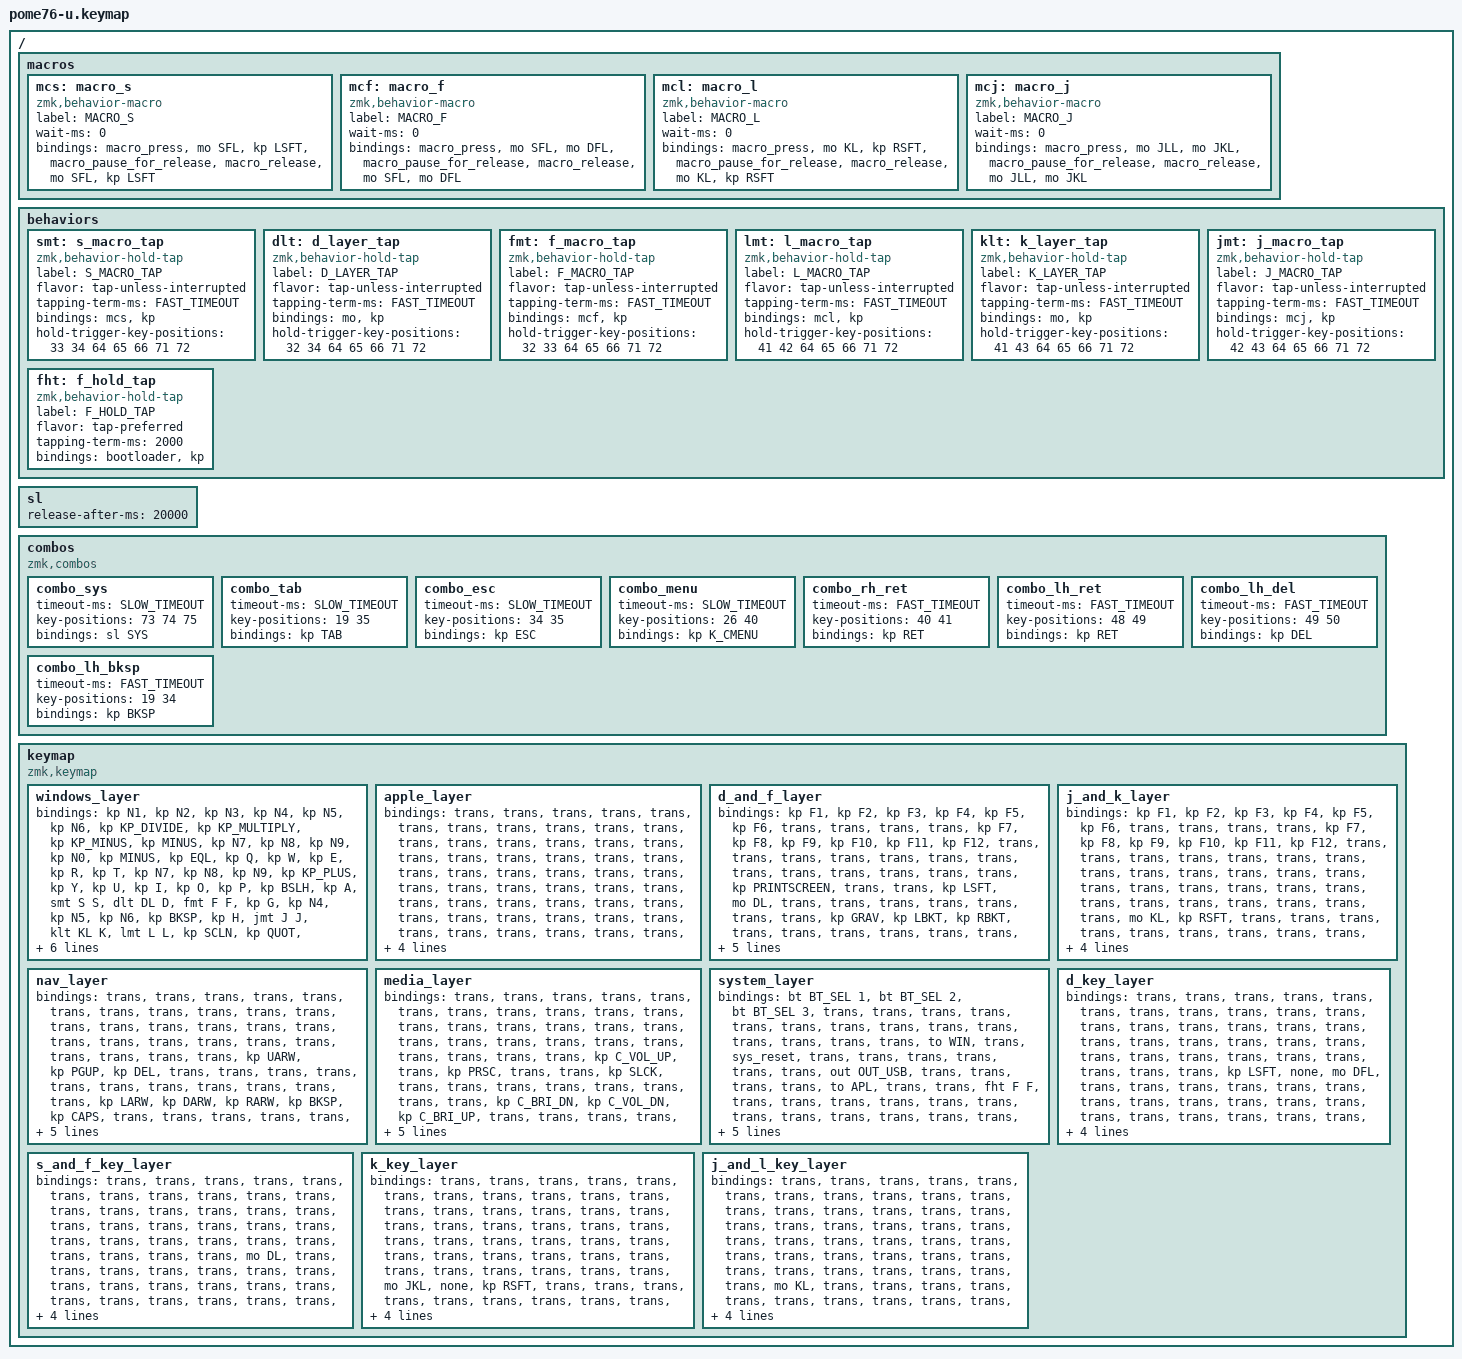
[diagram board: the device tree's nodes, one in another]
#include <behaviors.dtsi>
#include <dt-bindings/zmk/bt.h>
#include <dt-bindings/zmk/keys.h>
#include <dt-bindings/zmk/outputs.h>

// ***********************************************************************************
// Key positions
// ***********************************************************************************
// 19: R
// 26: U
// 32: S
// 41: J
// 46: Left Shift (start of Z row)
// 57: M
// 61: start of bottom row
// (64, 65, 66): left hand modifier keys
// 70: Space

// ***********************************************************************************
// Layer enums
// ***********************************************************************************
#define WIN 0     // Windows
#define APL 1     // Apple
#define DFL 2     // Layer that is controlled by the D or F keys
#define JKL 3     // Layer that is controlled by the J or K keys
#define NAV 4     // Navigation
#define MED 5     // Media
#define SYS 6     // System
#define DL  7     // Layer that is controlled by the D key
#define SFL 8     // Layer that is controlled by the S or F keys
#define KL  9     // Layer that is controlled by the K key
#define JLL 10    // Layer that is controlled by the J or L keys

// ***********************************************************************************
// Timeouts
// ***********************************************************************************
// FAST_TIMEOUT is very short.
// It is used mostly for combos involving keys that might occur in sequence while typing common words.
// For example SD => Shift, because S and D occur next to each other common words like "sounDS".
// See mercury-u.keymap for the early history of FAST_TIMEOUT values.
// [12Nov2023] 50 => 35 ms Decrease timout due to (fairly rare) unintentional combo activations. E.g. the word "sounds" comes out as "sounSHIFT".
// [03Nov2024] 35 => 42 ms Increase timout. I physically modified my switches by adding shims to the center posts to reduce key travel. After
//   this modification, SD is sometimes coming out as "sd" instead of the intended LShift.
// [26Dec2024] 42 => 46 ms Increase timout. ,. => Enter sometimes comes out as ,. instead of the intended Enter
#define FAST_TIMEOUT 42

// SLOW_TIMEOUT is very long.
// It is mostly used for combos involving keys that are controlled by the same finger, and should therefore by typed relatively slowly and in strict sequence.
// For example RG => TAB, because R and G are both actuated by the left index finger.
// [?? 2022] Initialize 200 ms. Naively chosen to mimic QMK's default value of TAPPING_TERM.
// [14Feb2025] Lower to 70 ms. Long timeout interferes with gaming. For example, F+G = ESC doesn't work well with F = Nova in Diablo 2.
#define SLOW_TIMEOUT 70

/ {
    // ***********************************************************************************
    // Macros
    // ***********************************************************************************
    macros {

        // ***********************************************************************************
        // Combo based layers
        // ***********************************************************************************
        mcs: macro_s {
            label = "MACRO_S";
            compatible = "zmk,behavior-macro";
            #binding-cells = <0>;
            wait-ms = <0>;
            bindings
                = <&macro_press &mo SFL &kp LSFT>
                , <&macro_pause_for_release>
                , <&macro_release &mo SFL &kp LSFT>
                ;
        };

        mcf: macro_f {
            label = "MACRO_F";
            compatible = "zmk,behavior-macro";
            #binding-cells = <0>;
            wait-ms = <0>;
            bindings
                = <&macro_press &mo SFL &mo DFL>
                , <&macro_pause_for_release>
                , <&macro_release &mo SFL &mo DFL>
                ;
        };

        mcl: macro_l {
            label = "MACRO_L";
            compatible = "zmk,behavior-macro";
            #binding-cells = <0>;
            wait-ms = <0>;
            bindings
                = <&macro_press &mo KL &kp RSFT>
                , <&macro_pause_for_release>
                , <&macro_release &mo KL &kp RSFT>
                ;
        };

        mcj: macro_j {
            label = "MACRO_J";
            compatible = "zmk,behavior-macro";
            #binding-cells = <0>;
            wait-ms = <0>;
            bindings
                = <&macro_press &mo JLL &mo JKL>
                , <&macro_pause_for_release>
                , <&macro_release &mo JLL &mo JKL>
                ;
        };
    };

    // ***********************************************************************************
    // Hold-Taps
    // ***********************************************************************************
    behaviors {

        // ***********************************************************************************
        // Combo based layers
        // ***********************************************************************************
        smt: s_macro_tap {
            compatible = "zmk,behavior-hold-tap";
            label = "S_MACRO_TAP";
            #binding-cells = <2>;
            flavor = "tap-unless-interrupted";
            tapping-term-ms = <FAST_TIMEOUT>;
            bindings = <&mcs>, <&kp>;
            hold-trigger-key-positions = <33 34 64 65 66 71 72>;
        };

        dlt: d_layer_tap {
            compatible = "zmk,behavior-hold-tap";
            label = "D_LAYER_TAP";
            #binding-cells = <2>;
            flavor = "tap-unless-interrupted";
            tapping-term-ms = <FAST_TIMEOUT>;
            bindings = <&mo>, <&kp>;
            hold-trigger-key-positions = <32 34 64 65 66 71 72>;
        };

        fmt: f_macro_tap {
            compatible = "zmk,behavior-hold-tap";
            label = "F_MACRO_TAP";
            #binding-cells = <2>;
            flavor = "tap-unless-interrupted";
            tapping-term-ms = <FAST_TIMEOUT>;
            bindings = <&mcf>, <&kp>;
            hold-trigger-key-positions = <32 33 64 65 66 71 72>;
        };

        lmt: l_macro_tap {
            compatible = "zmk,behavior-hold-tap";
            label = "L_MACRO_TAP";
            #binding-cells = <2>;
            flavor = "tap-unless-interrupted";
            tapping-term-ms = <FAST_TIMEOUT>;
            bindings = <&mcl>, <&kp>;
            hold-trigger-key-positions = <41 42 64 65 66 71 72>;
        };

        klt: k_layer_tap {
            compatible = "zmk,behavior-hold-tap";
            label = "K_LAYER_TAP";
            #binding-cells = <2>;
            flavor = "tap-unless-interrupted";
            tapping-term-ms = <FAST_TIMEOUT>;
            bindings = <&mo>, <&kp>;
            hold-trigger-key-positions = <41 43 64 65 66 71 72>;
        };

        jmt: j_macro_tap {
            compatible = "zmk,behavior-hold-tap";
            label = "J_MACRO_TAP";
            #binding-cells = <2>;
            flavor = "tap-unless-interrupted";
            tapping-term-ms = <FAST_TIMEOUT>;
            bindings = <&mcj>, <&kp>;
            hold-trigger-key-positions = <42 43 64 65 66 71 72>;
        };

        // ***********************************************************************************
        // Other hold-taps
        // ***********************************************************************************

        // F-key (in system_layer): hold = flash, tap = F
        fht: f_hold_tap {
            compatible = "zmk,behavior-hold-tap";
            label = "F_HOLD_TAP";
            #binding-cells = <2>;
            flavor = "tap-preferred";
            tapping-term-ms = <2000>;
            bindings = <&bootloader>, <&kp>;
        };
    };

    // sl stands for Sticky Layer.
    sl {
        release-after-ms = <20000>; // 20 seconds
    };

    // ***********************************************************************************
    // Combos
    // ***********************************************************************************
    combos {
        compatible = "zmk,combos";

        combo_sys {
            timeout-ms = <SLOW_TIMEOUT>;
            key-positions = <73 74 75>; /* lower right hand corner */
            bindings = <&sl SYS>;
        };
        combo_tab {
            timeout-ms = <SLOW_TIMEOUT>;
            key-positions = <19 35>; /* R G */
            bindings = <&kp TAB>;
        };
        combo_esc {
            timeout-ms = <SLOW_TIMEOUT>;
            key-positions = <34 35>; /* F G */
            bindings = <&kp ESC>;
        };
        combo_menu {
            timeout-ms = <SLOW_TIMEOUT>;
            key-positions = <26 40>; /* U H */
            bindings = <&kp K_CMENU>;
        };

        // Combos to make one-handed operation easier
        combo_rh_ret {
            // Previous timeouts:
            timeout-ms = <FAST_TIMEOUT>;
            key-positions = <40 41>; /* h j */
            bindings = <&kp RET>;
        };

        combo_lh_ret {
            // Previous timeouts:
            timeout-ms = <FAST_TIMEOUT>;
            key-positions = <48 49>; /* X C */
            bindings = <&kp RET>;
        };
        combo_lh_del {
            // Previous timeouts:
            timeout-ms = <FAST_TIMEOUT>;
            key-positions = <49 50>; /* C V */
            bindings = <&kp DEL>;
        };
        combo_lh_bksp {
            // Previous timeouts:
            timeout-ms = <FAST_TIMEOUT>;
            key-positions = <19 34 >; /* R F */
            bindings = <&kp BKSP>;
        };
    };

    // ***********************************************************************************
    // Keymaps
    // ***********************************************************************************
    keymap {
        compatible = "zmk,keymap";

        windows_layer {
            bindings = <
&kp N1        &kp N2        &kp N3        &kp N4        &kp N5        &kp N6       &kp KP_DIVIDE &kp KP_MULTIPLY &kp KP_MINUS &kp MINUS     &kp N7        &kp N8        &kp N9        &kp N0        &kp MINUS     &kp EQL
&kp Q         &kp W         &kp E         &kp R         &kp T         &kp N7        &kp N8        &kp N9        &kp KP_PLUS   &kp Y         &kp U         &kp I         &kp O         &kp P         &kp BSLH
&kp A         &smt S S      &dlt DL D     &fmt F F      &kp G         &kp N4        &kp N5        &kp N6        &kp BKSP      &kp H         &jmt J J      &klt KL K     &lmt L L      &kp SCLN      &kp QUOT
&kp LSFT      &kp Z         &kp X         &kp C         &kp V         &kp B         &kp N1        &kp N2        &kp N3        &kp BSLH      &kp N         &kp M         &kp CMMA      &kp DOT       &kp FSLH
&kp BKSP      &kp DEL       &kp SPC       &kp LGUI      &kp LCTL      &kp LALT      &kp SPC       &kp N0        &kp DOT       &kp SPC       &mo NAV       &mo MED       &kp BKSP      &kp DEL       &kp RET
            >;
        };

        apple_layer {
            bindings = <
&trans        &trans        &trans        &trans        &trans        &trans        &trans        &trans        &trans        &trans        &trans        &trans        &trans        &trans        &trans        &trans
&trans        &trans        &trans        &trans        &trans        &trans        &trans        &trans        &trans        &trans        &trans        &trans        &trans        &trans        &trans
&trans        &trans        &trans        &trans        &trans        &trans        &trans        &trans        &trans        &trans        &trans        &trans        &trans        &trans        &trans
&trans        &trans        &trans        &trans        &trans        &trans        &trans        &trans        &trans        &trans        &trans        &trans        &trans        &trans        &trans
&trans        &trans        &trans        &kp LALT      &kp LGUI      &kp LCTL      &trans        &trans        &trans        &trans        &trans        &trans        &trans        &trans        &trans
            >;
        };

        d_and_f_layer {
            bindings = <
&kp F1        &kp F2        &kp F3        &kp F4        &kp F5        &kp F6        &trans        &trans        &trans        &trans        &kp F7        &kp F8        &kp F9        &kp F10       &kp F11       &kp F12
&trans        &trans        &trans        &trans        &trans        &trans        &trans        &trans        &trans        &trans        &trans        &trans        &trans     &kp PRINTSCREEN  &trans
&trans        &kp LSFT      &mo DL        &trans        &trans        &trans        &trans        &trans        &trans        &trans        &kp GRAV      &kp LBKT      &kp RBKT      &trans        &trans
&trans        &trans        &trans        &trans        &trans        &trans        &trans        &trans        &trans        &trans        &trans        &trans        &trans        &trans        &trans
&trans        &trans        &trans        &trans        &trans        &trans        &trans        &trans        &trans        &trans        &trans        &trans        &trans        &trans        &trans
            >;
        };

        j_and_k_layer {
            bindings = <
&kp F1        &kp F2        &kp F3        &kp F4        &kp F5        &kp F6        &trans        &trans        &trans        &trans        &kp F7        &kp F8        &kp F9        &kp F10       &kp F11       &kp F12
&trans        &trans        &trans        &trans        &trans        &trans        &trans        &trans        &trans        &trans        &trans        &trans        &trans        &trans        &trans
&trans        &trans        &trans        &trans        &trans        &trans        &trans        &trans        &trans        &trans        &trans        &mo KL        &kp RSFT      &trans        &trans
&trans        &trans        &trans        &trans        &trans        &trans        &trans        &trans        &trans        &trans        &trans        &trans        &trans        &trans        &trans
&trans        &trans        &trans        &trans        &trans        &trans        &trans        &trans        &trans        &trans        &trans        &trans        &trans        &trans        &trans
            >;
        };

        nav_layer {
            bindings = <
&trans        &trans        &trans        &trans        &trans        &trans        &trans        &trans        &trans        &trans        &trans        &trans        &trans        &trans        &trans        &trans
&trans        &trans        &trans        &trans        &trans        &trans        &trans        &trans        &trans        &trans        &trans        &kp UARW      &kp PGUP      &kp DEL       &trans
&trans        &trans        &trans        &trans        &trans        &trans        &trans        &trans        &trans        &trans        &kp LARW      &kp DARW      &kp RARW      &kp BKSP      &kp CAPS
&trans        &trans        &trans        &trans        &trans        &trans        &trans        &trans        &trans        &trans        &kp PGDN      &kp RGUI      &kp HOME      &kp END       &kp RET
&trans        &trans        &trans        &trans        &trans        &trans        &trans        &trans        &trans        &trans        &trans        &trans        &trans        &trans        &trans
            >;
        };

        media_layer {
            bindings = <
&trans        &trans        &trans        &trans        &trans        &trans        &trans        &trans        &trans        &trans        &trans        &trans        &trans        &trans        &trans        &trans
&trans        &trans        &trans        &trans        &trans        &trans        &trans        &trans        &trans        &trans        &trans        &kp C_VOL_UP  &trans        &kp PRSC      &trans
&trans        &kp SLCK      &trans        &trans        &trans        &trans        &trans        &trans        &trans        &trans        &kp C_BRI_DN  &kp C_VOL_DN  &kp C_BRI_UP  &trans        &trans
&trans        &trans        &trans        &trans        &trans        &trans        &trans        &trans        &trans        &trans        &kp INS       &kp C_MUTE    &trans        &trans        &trans
&trans        &trans        &trans        &trans        &trans        &trans        &trans        &trans        &trans        &trans        &trans        &trans        &trans        &trans        &trans
            >;
        };

        system_layer {
            bindings = <
&bt BT_SEL 1  &bt BT_SEL 2  &bt BT_SEL 3  &trans        &trans        &trans        &trans        &trans        &trans        &trans        &trans        &trans        &trans        &trans        &trans        &trans
&trans        &to WIN       &trans        &sys_reset    &trans        &trans        &trans        &trans        &trans        &trans        &out OUT_USB  &trans        &trans        &trans        &trans
&to APL       &trans        &trans        &fht F F      &trans        &trans        &trans        &trans        &trans        &trans        &trans        &trans        &trans        &trans        &trans
&trans        &trans        &trans        &bt BT_CLR    &trans        &out OUT_BLE  &trans        &trans        &trans        &trans        &trans        &trans        &trans        &trans        &trans
&trans        &trans        &trans        &trans        &trans        &trans        &trans        &trans        &trans        &trans        &trans        &trans        &trans        &trans        &trans
            >;
        };

        d_key_layer {
            bindings = <
&trans        &trans        &trans        &trans        &trans        &trans        &trans        &trans        &trans        &trans        &trans        &trans        &trans        &trans        &trans        &trans
&trans        &trans        &trans        &trans        &trans        &trans        &trans        &trans        &trans        &trans        &trans        &trans        &trans        &trans        &trans
&trans        &kp LSFT      &none         &mo DFL       &trans        &trans        &trans        &trans        &trans        &trans        &trans        &trans        &trans        &trans        &trans
&trans        &trans        &trans        &trans        &trans        &trans        &trans        &trans        &trans        &trans        &trans        &trans        &trans        &trans        &trans
&trans        &trans        &trans        &trans        &trans        &trans        &trans        &trans        &trans        &trans        &trans        &trans        &trans        &trans        &trans
            >;
        };

        s_and_f_key_layer {
            bindings = <
&trans        &trans        &trans        &trans        &trans        &trans        &trans        &trans        &trans        &trans        &trans        &trans        &trans        &trans        &trans        &trans
&trans        &trans        &trans        &trans        &trans        &trans        &trans        &trans        &trans        &trans        &trans        &trans        &trans        &trans        &trans
&trans        &trans        &mo DL        &trans        &trans        &trans        &trans        &trans        &trans        &trans        &trans        &trans        &trans        &trans        &trans
&trans        &trans        &trans        &trans        &trans        &trans        &trans        &trans        &trans        &trans        &trans        &trans        &trans        &trans        &trans
&trans        &trans        &trans        &trans        &trans        &trans        &trans        &trans        &trans        &trans        &trans        &trans        &trans        &trans        &trans
            >;
        };

        k_key_layer {
            bindings = <
&trans        &trans        &trans        &trans        &trans        &trans        &trans        &trans        &trans        &trans        &trans        &trans        &trans        &trans        &trans        &trans
&trans        &trans        &trans        &trans        &trans        &trans        &trans        &trans        &trans        &trans        &trans        &trans        &trans        &trans        &trans
&trans        &trans        &trans        &trans        &trans        &trans        &trans        &trans        &trans        &trans        &mo JKL       &none         &kp RSFT      &trans        &trans
&trans        &trans        &trans        &trans        &trans        &trans        &trans        &trans        &trans        &trans        &trans        &trans        &trans        &trans        &trans
&trans        &trans        &trans        &trans        &trans        &trans        &trans        &trans        &trans        &trans        &trans        &trans        &trans        &trans        &trans
            >;
        };

        j_and_l_key_layer {
            bindings = <
&trans        &trans        &trans        &trans        &trans        &trans        &trans        &trans        &trans        &trans        &trans        &trans        &trans        &trans        &trans        &trans
&trans        &trans        &trans        &trans        &trans        &trans        &trans        &trans        &trans        &trans        &trans        &trans        &trans        &trans        &trans
&trans        &trans        &trans        &trans        &trans        &trans        &trans        &trans        &trans        &trans        &trans        &mo KL        &trans        &trans        &trans
&trans        &trans        &trans        &trans        &trans        &trans        &trans        &trans        &trans        &trans        &trans        &trans        &trans        &trans        &trans
&trans        &trans        &trans        &trans        &trans        &trans        &trans        &trans        &trans        &trans        &trans        &trans        &trans        &trans        &trans
            >;
        };
    };
};
